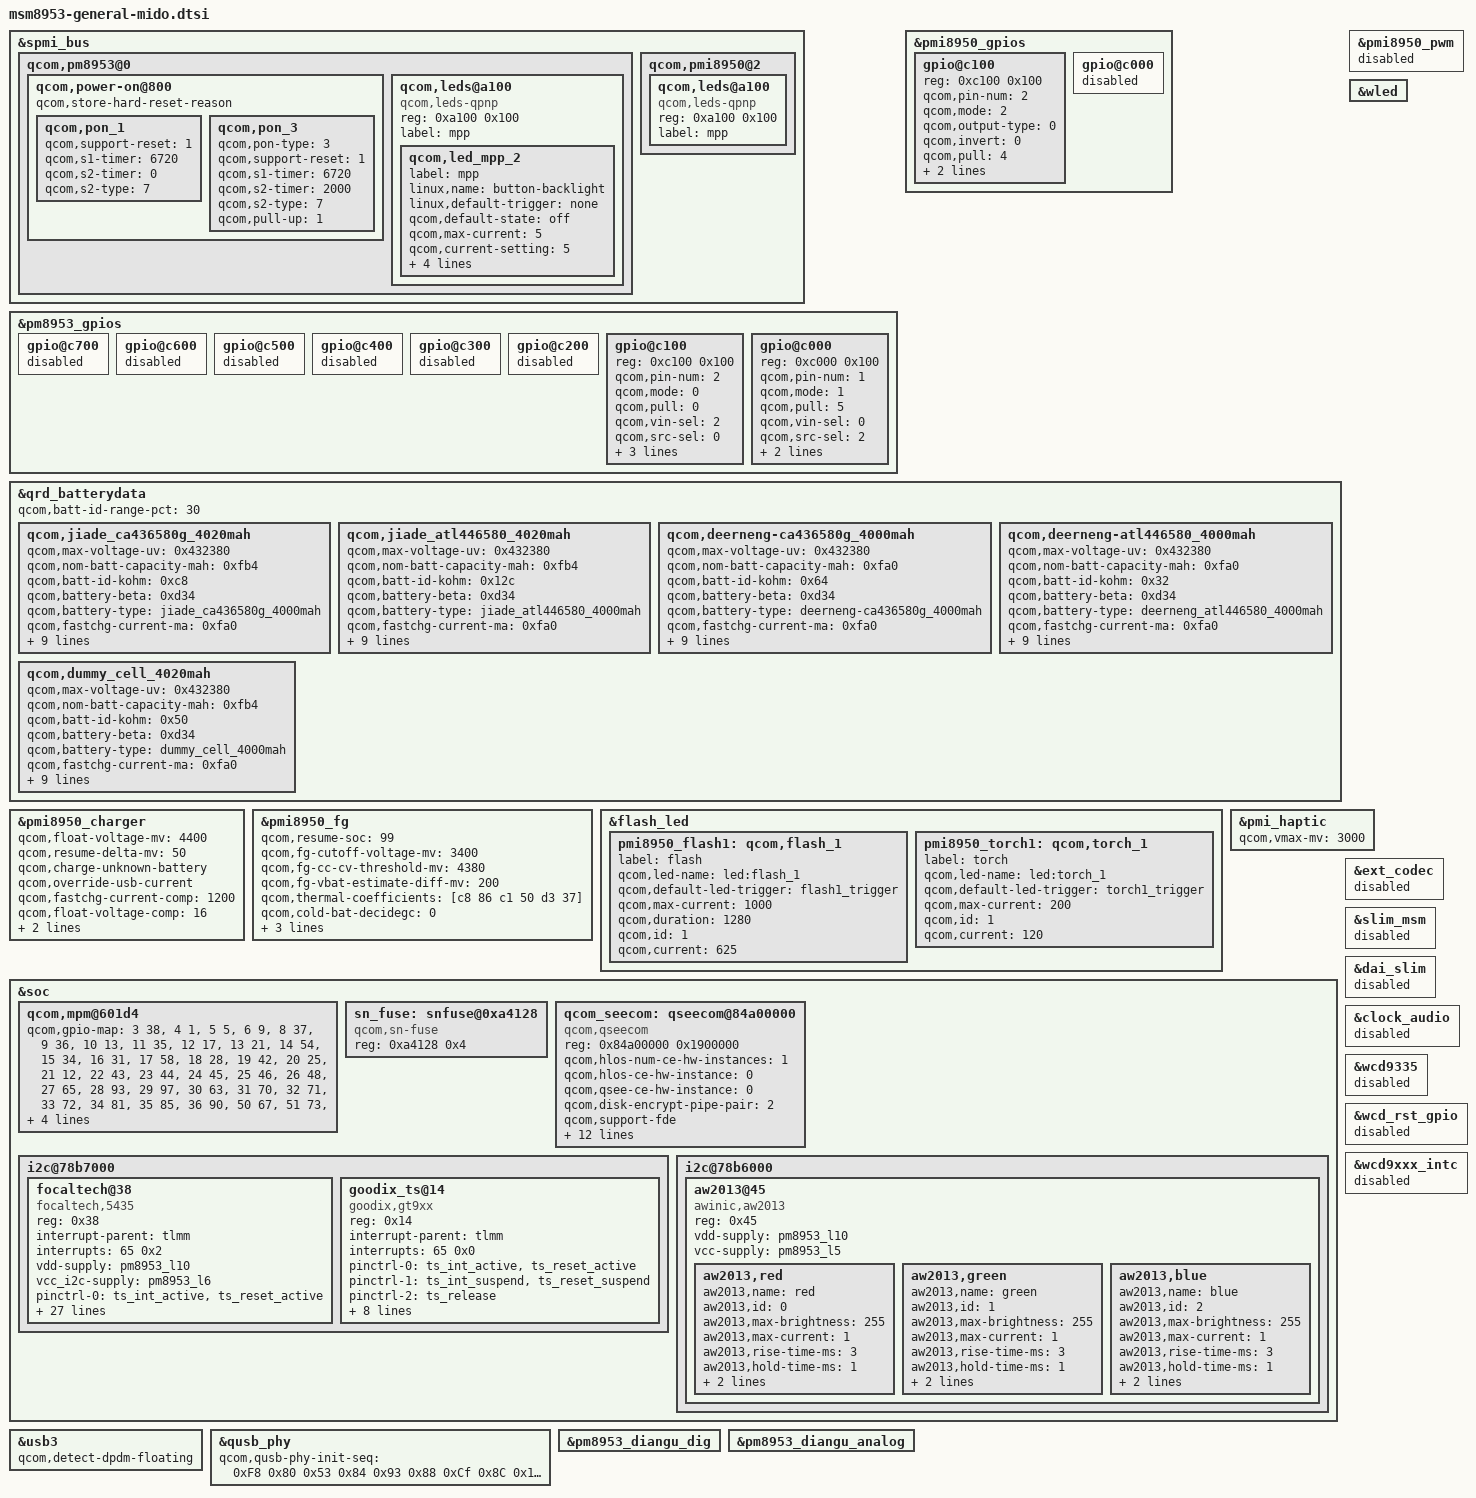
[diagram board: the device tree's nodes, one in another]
/* Copyright (c) 2017, The Linux Foundation. All rights reserved.
 *
 * This program is free software; you can redistribute it and/or modify
 * it under the terms of the GNU General Public License version 2 and
 * only version 2 as published by the Free Software Foundation.
 *
 * This program is distributed in the hope that it will be useful,
 * but WITHOUT ANY WARRANTY; without even the implied warranty of
 * MERCHANTABILITY or FITNESS FOR A PARTICULAR PURPOSE.  See the
 * GNU General Public License for more details.
 */

&spmi_bus {
	qcom,pm8953@0 {
		qcom,power-on@800 {
                       qcom,store-hard-reset-reason;
			qcom,pon_1 {
				qcom,support-reset = <1>;
				qcom,s1-timer = <6720>;
				qcom,s2-timer = <0>;
				qcom,s2-type = <7>;
			};
			qcom,pon_3 {
				qcom,pon-type = <3>;
				qcom,support-reset = <1>;
				qcom,s1-timer = <6720>;
				qcom,s2-timer = <2000>;
				qcom,s2-type = <7>;
				qcom,pull-up = <1>;
			};
		};
                qcom,leds@a100 {
                        status = "okay";
                        compatible = "qcom,leds-qpnp";
                        reg = <0xa100 0x100>;
                        label = "mpp";
                        qcom,led_mpp_2 {
                                label = "mpp";
                                linux,name = "button-backlight";
                                linux,default-trigger = "none";
                                qcom,default-state = "off";
                                qcom,max-current = <5>;
                                qcom,current-setting = <5>;
                                qcom,id = <6>;
                                qcom,mode = "manual";
                                qcom,source-sel = <1>;
                                qcom,mode-ctrl = <0x61>;
                        };
                };
		/delete-node/ qcom,pm8953_typec@bf00;
	};

	qcom,pmi8950@2 {
		qcom,leds@a100 {
			compatible = "qcom,leds-qpnp";
			reg = <0xa100 0x100>;
			label = "mpp";
			/delete-node/ qcom,led_mpp_2;
		};
	};
};

&pm8953_gpios {
	gpio@c700 {
		status = "disabled";
	};
    
    gpio@c600 {
		status = "disabled";
	};
    
    gpio@c500 {
		status = "disabled";
	};
    
    gpio@c400 {
		status = "disabled";
	};
    
    gpio@c300 {
		status = "disabled";
	};
    
    gpio@c200 {
		status = "disabled";
	};
    
    gpio@c100 {
        reg = <0xc100 0x100>;
        qcom,pin-num = <2>;
        qcom,mode = <0>;
        qcom,pull = <0>;
        qcom,vin-sel = <2>;
        qcom,src-sel = <0>;
        qcom,master-en = <1>;
        qcom,out-strength = <3>;
        qcom,output-type = <0>;
        status = "okay";
    };
    
    gpio@c000 {
        reg = <0xc000 0x100>;
        qcom,pin-num = <1>;
        qcom,mode = <1>;
        qcom,pull = <5>;
        qcom,vin-sel = <0>;
        qcom,src-sel = <2>;
        qcom,master-en = <1>;
        qcom,out-strength = <2>;
        status = "okay";
    };
};

&pmi8950_gpios {
    gpio@c100 {
        reg = <0xc100 0x100>;
        qcom,pin-num = <2>;
        qcom,mode = <2>;
        qcom,output-type = <0>;
        qcom,invert = <0>;
        qcom,pull = <4>;
        qcom,out-strength = <3>;
        qcom,master-en = <1>;
        status = "okay";
    };
    
	gpio@c000 {
		status = "disabled";
	};
};

&qrd_batterydata {
	qcom,batt-id-range-pct = <30>;
    
	qcom,jiade_ca436580g_4020mah {
        qcom,max-voltage-uv = <0x432380>;
        qcom,nom-batt-capacity-mah = <0xfb4>;
        qcom,batt-id-kohm = <0xc8>;
        qcom,battery-beta = <0xd34>;
        qcom,battery-type = "jiade_ca436580g_4000mah";
        qcom,fastchg-current-ma = <0xfa0>;
        qcom,fg-cc-cv-threshold-mv = <0x1126>;
        qcom,chg-rslow-comp-c1 = <0x3840d2>;
        qcom,chg-rslow-comp-c2 = <0x627b75>;
        qcom,chg-rs-to-rslow = <0xb9ddd>;
        qcom,chg-rslow-comp-thr = <0xb7>;
        qcom,checksum = <0x952e>;
        qcom,gui-version = "PMI8950GUI - 2.0.0.16";
        qcom,fg-profile-data = <0xf0836d7d 0x9881227c 0x5d83656c 0x4b839b8d 0xeb813a9a 0x85bc71c8 0x5b110188 0x977da281 0x217c5283 0xa969ae79 0xbe861f82 0x739abebd 0x2fcb5a0e 0xdc0f8359 0x1470eefc 0x47447b3f 0xeb400000 0x5466930 0xfe1a0000 0x0 0x0 0x2b6bd169 0x6a731291 0x93776c71 0x46765f71 0x5e75426b 0x96666a2 0x24da5b73 0x5da0710c 0x2800ff36 0xf0113003 0xc>;
    };

    qcom,jiade_atl446580_4020mah {
        qcom,max-voltage-uv = <0x432380>;
        qcom,nom-batt-capacity-mah = <0xfb4>;
        qcom,batt-id-kohm = <0x12c>;
        qcom,battery-beta = <0xd34>;
        qcom,battery-type = "jiade_atl446580_4000mah";
        qcom,fastchg-current-ma = <0xfa0>;
        qcom,fg-cc-cv-threshold-mv = <0x1126>;
        qcom,chg-rslow-comp-c1 = <0x2ddb09>;
        qcom,chg-rslow-comp-c2 = <0x3cda94>;
        qcom,chg-rs-to-rslow = <0xc8771>;
        qcom,chg-rslow-comp-thr = <0x9f>;
        qcom,checksum = <0xb43>;
        qcom,gui-version = "PMI8950GUI - 2.0.0.16";
        qcom,fg-profile-data = <0xec833f7d 0x7181f677 0x55839752 0x52804587 0x1682ab9a 0xf3bd44cb 0x5b0e0588 0xeb7dde81 0x557c4f83 0x42704270 0x55845082 0x9299d5bc 0xb0c95a0d 0xb50f5059 0x1470eefc 0x833f1d3e 0x7b400000 0x4345bc30 0x3f290000 0x0 0x0 0xec6aed69 0x8978f789 0x546f5463 0x6b610a80 0xf06cd25b 0xa17c2ea1 0x1a1162e3 0x5fa0710c 0x2800ff36 0xf0113003 0xc>;
    };

    qcom,deerneng-ca436580g_4000mah {
        qcom,max-voltage-uv = <0x432380>;
        qcom,nom-batt-capacity-mah = <0xfa0>;
        qcom,batt-id-kohm = <0x64>;
        qcom,battery-beta = <0xd34>;
        qcom,battery-type = "deerneng-ca436580g_4000mah";
        qcom,fastchg-current-ma = <0xfa0>;
        qcom,fg-cc-cv-threshold-mv = <0x1126>;
        qcom,chg-rslow-comp-c1 = <0x2eec11>;
        qcom,chg-rslow-comp-c2 = <0x4856fb>;
        qcom,chg-rs-to-rslow = <0xa7bf6>;
        qcom,chg-rslow-comp-thr = <0xac>;
        qcom,checksum = <0xc816>;
        qcom,gui-version = "PMI8950GUI - 2.0.0.16";
        qcom,fg-profile-data = <0xf183767d 0x8d81017c 0x5b831667 0xe582728d 0xa82fa99 0x8bbcabc8 0x5a0f0288 0xbd7dbe81 0x317c4f83 0xd6bff72 0x3852782 0x3e9a7dbd 0xbeca5a0e 0xcd0fbb58 0x1470eefc 0x4545e937 0x363b0000 0x5345392a 0xdd370000 0x0 0x0 0x5c6a7769 0x9c631d80 0xc4675a60 0xcf629e79 0xcc640359 0x7c7e7a91 0x1d0161f7 0x5da0710c 0x2800ff36 0xf0113003 0xc>;
    };

    qcom,deerneng-atl446580_4000mah {
        qcom,max-voltage-uv = <0x432380>;
        qcom,nom-batt-capacity-mah = <0xfa0>;
        qcom,batt-id-kohm = <0x32>;
        qcom,battery-beta = <0xd34>;
        qcom,battery-type = "deerneng_atl446580_4000mah";
        qcom,fastchg-current-ma = <0xfa0>;
        qcom,fg-cc-cv-threshold-mv = <0x1126>;
        qcom,chg-rslow-comp-c1 = <0x30d3ae>;
        qcom,chg-rslow-comp-c2 = <0x43103e>;
        qcom,chg-rs-to-rslow = <0xca280>;
        qcom,chg-rslow-comp-thr = <0xa2>;
        qcom,checksum = <0x8aaf>;
        qcom,gui-version = "PMI8950GUI - 2.0.0.16";
        qcom,fg-profile-data = <0xdf83c87c 0x19815577 0x6183ba6f 0x36895c94 0x3282b299 0xb3bc3ec9 0x550ffa83 0x497d5b81 0xa4775f83 0xab5deb83 0xc28f4982 0x89a75bd 0xaeca520d 0xb60f6859 0x1470eefc 0x6e3e0c45 0xe6410000 0x5a461c30 0x1e2a0000 0x0 0x0 0x6f6bfb69 0x9971a98b 0xfb75d06b 0x216d1579 0x2a6f2d68 0x583504a8 0x214163ff 0x64a0710c 0x2800ff36 0xf0113003 0xc>;
    };

    qcom,dummy_cell_4020mah {
        qcom,max-voltage-uv = <0x432380>;
        qcom,nom-batt-capacity-mah = <0xfb4>;
        qcom,batt-id-kohm = <0x50>;
        qcom,battery-beta = <0xd34>;
        qcom,battery-type = "dummy_cell_4000mah";
        qcom,fastchg-current-ma = <0xfa0>;
        qcom,fg-cc-cv-threshold-mv = <0x1126>;
        qcom,chg-rslow-comp-c1 = <0x3840d2>;
        qcom,chg-rslow-comp-c2 = <0x627b75>;
        qcom,chg-rs-to-rslow = <0xb9ddd>;
        qcom,chg-rslow-comp-thr = <0xb7>;
        qcom,checksum = <0x952e>;
        qcom,gui-version = "PMI8950GUI - 2.0.0.16";
        qcom,fg-profile-data = <0xf0836d7d 0x9881227c 0x5d83656c 0x4b839b8d 0xeb813a9a 0x85bc71c8 0x5b110188 0x977da281 0x217c5283 0xa969ae79 0xbe861f82 0x739abebd 0x2fcb5a0e 0xdc0f8359 0x1470eefc 0x47447b3f 0xeb400000 0x5466930 0xfe1a0000 0x0 0x0 0x2b6bd169 0x6a731291 0x93776c71 0x46765f71 0x5e75426b 0x96666a2 0x24da5b73 0x5da0710c 0x2800ff36 0xf0113003 0xc>;
    };
	/delete-node/ qcom,qrd_msm8937_sku1_2920mah;

};


&pmi8950_charger {
	qcom,float-voltage-mv = <4400>;
	qcom,resume-delta-mv = <50>;
	qcom,charge-unknown-battery;
	qcom,override-usb-current;
	qcom,fastchg-current-comp = <1200>;
	qcom,float-voltage-comp = <16>;
	qcom,thermal-mitigation = <3000 2500 2000 2000 1000 500 0>;
	/delete-property/ qcom,parallel-usb-min-current-ma;
	/delete-property/ qcom,parallel-usb-9v-min-current-ma;
	/delete-property/ qcom,parallel-allowed-lowering-ma;
	/delete-property/ qcom,chg-led-sw-controls;
	/delete-property/ qcom,chg-led-support;
	/delete-property/ qcom,external-typec;
	/delete-property/ qcom,typec-psy-name;
	/delete-property/ qcom,autoadjust-vfloat;
};

&pmi8950_fg {
	qcom,resume-soc = <99>;
	qcom,fg-cutoff-voltage-mv = <3400>;
	qcom,fg-cc-cv-threshold-mv = <4380>;
	qcom,fg-vbat-estimate-diff-mv = <200>;
	qcom,thermal-coefficients = [c8 86 c1 50 d3 37];
	qcom,cold-bat-decidegc = <0>;
	qcom,cool-bat-decidegc = <150>;
	qcom,warm-bat-decidegc = <450>;
	qcom,fg-restore-batt-info;

};

&pmi8950_pwm {
	status = "disabled";
};

&wled {
	/delete-property/ qcom,en-ext-pfet-sc-pro;
};

&flash_led {
	pmi8950_flash1: qcom,flash_1 {
		label = "flash";
		qcom,led-name = "led:flash_1";
		qcom,default-led-trigger = "flash1_trigger";
		qcom,max-current = <1000>;
		qcom,duration = <1280>;
		qcom,id = <1>;
		qcom,current = <625>;
	};
	
	pmi8950_torch1: qcom,torch_1 {
		label = "torch";
		qcom,led-name = "led:torch_1";
		qcom,default-led-trigger = "torch1_trigger";
		qcom,max-current = <200>;
		qcom,id = <1>;
		qcom,current = <120>;
	};
};

&pmi_haptic {
	qcom,vmax-mv = <3000>;
};

&soc {
	qcom,mpm@601d4 {
		qcom,gpio-map = <3  38 >,
                        <4  1 >,
                        <5  5 >,
                        <6  9 >,
                        <8  37>,
                        <9  36>,
                        <10  13>,
                        <11  35>,
                        <12  17>,
                        <13  21>,
                        <14  54>,
                        <15  34>,
                        <16  31>,
                        <17  58>,
                        <18  28>,
                        <19  42>,
                        <20  25>,
                        <21  12>,
                        <22  43>,
                        <23  44>,
                        <24  45>,
                        <25  46>,
                        <26  48>,
                        <27  65>,
                        <28  93>,
                        <29  97>,
                        <30  63>,
                        <31  70>,
                        <32  71>,
                        <33  72>,
                        <34  81>,
                        <35  85>,
                        <36  90>,
                        <50  67>,
                        <51  73>,
                        <52  74>,
                        <53  62>,
                        <59  59>,
                        <60  60>,
                        <61  61>,
                        <62  86>,
                        <63  87>,
                        <64  91>,
                        <65  129>,
                        <66  130>,
                        <67  131>,
                        <68  132>,
                        <69  133>,
                        <70  137>,
                        <71  138>,
                        <72  139>,
                        <73  140>,
                        <74  141>,
                        <0xff 24>, /* added by xiaomi */
                        <0xff 88>;
		};
	sn_fuse: snfuse@0xa4128 {
		compatible = "qcom,sn-fuse";
		reg = <0xa4128 0x4>;
		reg-names = "sn-base";
	};

	qcom_seecom: qseecom@84a00000 { /* renamed from caf qseecom@85b00000 */
                compatible = "qcom,qseecom";
                reg = <0x84a00000 0x1900000>; /* changed by xiaomi */
                reg-names = "secapp-region";
                qcom,hlos-num-ce-hw-instances = <1>;
                qcom,hlos-ce-hw-instance = <0>;
                qcom,qsee-ce-hw-instance = <0>;
                qcom,disk-encrypt-pipe-pair = <2>;
                qcom,support-fde;
                qcom,msm-bus,name = "qseecom-noc";
                qcom,msm-bus,num-cases = <4>;
                qcom,msm-bus,num-paths = <1>;
                qcom,support-bus-scaling;
                qcom,msm-bus,vectors-KBps =
                        <55 512 0 0>,
                        <55 512 0 0>,
                        <55 512 120000 1200000>,
                        <55 512 393600 3936000>;
                clocks = <&clock_gcc clk_crypto_clk_src>,
                         <&clock_gcc clk_gcc_crypto_clk>,
                         <&clock_gcc clk_gcc_crypto_ahb_clk>,
                         <&clock_gcc clk_gcc_crypto_axi_clk>;
                clock-names = "core_clk_src", "core_clk",
                                "iface_clk", "bus_clk";
                qcom,ce-opp-freq = <100000000>;
        };

        /delete-node/ qseecom@85b00000;

	i2c@78b7000 {
                focaltech@38 {
                        compatible = "focaltech,5435";
                        reg = <0x38>;
                        interrupt-parent = <&tlmm>;
                        interrupts = <65 0x2>;
                        vdd-supply = <&pm8953_l10>;
                        vcc_i2c-supply = <&pm8953_l6>;
                        /* pins used by touchscreen */
                        pinctrl-names = "pmx_ts_active","pmx_ts_suspend",
                                                        "pmx_ts_release";
                        pinctrl-0 = <&ts_int_active &ts_reset_active>;
                        pinctrl-1 = <&ts_int_suspend &ts_reset_suspend>;
                        pinctrl-2 = <&ts_release>;
                        focaltech,name = "ft5435";
                        focaltech,family-id = <0x54>;
                        focaltech,reset-gpio = <&tlmm 64 0x0>;
                        focaltech,irq-gpio = <&tlmm 65 0x2008>;
                        focaltech,display-coords = <0 0 1080 1920>;
                        focaltech,panel-coords = <0 0 1080 1920>;
                        focaltech,no-force-update;
                        focaltech,i2c-pull-up;
                        focaltech,group-id = <1>;
                        focaltech,hard-reset-delay-ms = <200>;
                        focaltech,soft-reset-delay-ms = <200>;
                        focaltech,num-max-touches = <10>;
                        focaltech,fw-delay-aa-ms = <2>;
                        focaltech,fw-delay-55-ms = <2>;
                        focaltech,fw-upgrade-id1 = <0x54>;
                        focaltech,fw-upgrade-id2 = <0x2c>;
                        focaltech,fw-delay-readid-ms = <10>;
                        focaltech,fw-delay-era-flsh-ms = <2000>;
                        focaltech,fw-auto-cal;
                        focaltech,fw-vkey-support;
                        focaltech,resume-in-workqueue;
                        focaltech,num-virtual-key = <3>;
                        focal,virtual_key_1 = <172 500 2040>;/*home*/
                        focal,virtual_key_2 = <139 200 2040>;/*menu*/
                        focal,virtual_key_3 = <158 800 2040>;/*back*/
                };

		goodix_ts@14 {
			compatible = "goodix,gt9xx";
			reg = <0x14>;
			interrupt-parent = <&tlmm>;
			interrupts = <65 0x0>;
			pinctrl-names = "pmx_ts_active","pmx_ts_suspend",
			"pmx_ts_release";
			pinctrl-0 = <&ts_int_active &ts_reset_active>;
			pinctrl-1 = <&ts_int_suspend &ts_reset_suspend>;
			pinctrl-2 = <&ts_release>;
			vdd_ana-supply = <&pm8953_l10>;
			vcc_i2c-supply = <&pm8953_l6>;
			goodix,rst-gpio = <&tlmm 64 0x0>;
			goodix,irq-gpio = <&tlmm 65 0x2008>;
			goodix,cfg-group0 = [45 38 04 80 07 0A 35 41 01 0A
					26 0B 5A 32 05 05 00 00 00 00
					00 00 05 14 14 26 14 8C 2E 0E
					4A 4C F4 0A F4 0A 00 BA 33 11
					00 00 00 00 00 05 03 28 78 96
					3A 1E 5A 8F 90 03 00 00 00 04
					CE 21 00 B0 29 28 98 34 00 87
					41 60 7B 51 00 7B 18 38 60 00
					F0 55 40 AA A0 27 00 04 53 00
					00 00 00 00 00 02 00 00 00 00
					00 00 00 00 00 00 3C 00 00 00
					00 28 02 04 06 08 0A 0C 0E 10
					12 14 16 18 1A 1C 00 00 00 00
					00 00 00 00 00 00 00 00 00 00
					00 00 00 02 04 06 08 0A 0C 0F
					10 12 13 14 16 18 1C 1D 1E 1F
					20 21 22 24 26 28 29 2A 00 00
					00 00 00 00 00 00 00 00 00 00
					00 00 00 00 23 01];
			goodix,cfg-group1 = [49 38 04 80 07 0A 3D 49 01 48
					50 0F 50 41 03 65 00 00 00 00
					00 00 0F 16 1A 23 14 87 27 DD
					50 52 E7 07 E7 07 00 42 33 91
					0A 00 00 00 00 83 C4 14 14 C8
					02 3C 64 8F D0 03 05 1E 00 04
					93 3F 00 8A 46 00 82 4D 00 7C
					55 00 76 5F 00 76 18 38 60 00
					F7 55 40 99 99 17 00 00 D1 00
					00 00 00 00 00 02 00 00 05 28
					00 00 00 00 00 28 64 00 00 00
					00 50 0C 0B 0A 09 08 07 06 05
					04 03 02 01 00 0D 0E 0F 10 11
					12 13 14 15 16 17 18 19 1A FF
					FF FF 29 28 24 22 20 1F 1E 0A
					08 06 05 04 02 00 FF FF FF 00
					00 00 00 00 00 00 00 00 28 32
					3C 10 23 28 0F 00 00 00 00 00
					00 00 0F 4B 00 00 00 00 00 00
					1E 50 00 00 00 05 00 00 00 00
					01 14 78 1A 19 3C 28 00 00 00
					00 00 00 00 00 00 00 00 00 00
					00 00 00 00 00 00 83 01];
		};

        };

	i2c@78b6000 { /* BLSP1 QUP3 */
                aw2013@45 {
                        compatible = "awinic,aw2013";
                        reg = <0x45>;
                        vdd-supply = <&pm8953_l10>;
                        vcc-supply = <&pm8953_l5>;

                        aw2013,red {
                                aw2013,name = "red";
                                aw2013,id = <0>;
                                aw2013,max-brightness = <255>;
                                aw2013,max-current = <1>;
                                aw2013,rise-time-ms = <3>;
                                aw2013,hold-time-ms = <1>;
                                aw2013,fall-time-ms = <3>;
                                aw2013,off-time-ms = <3>;
                        };

                        aw2013,green {
                                aw2013,name = "green";
                                aw2013,id = <1>;
                                aw2013,max-brightness = <255>;
                                aw2013,max-current = <1>;
                                aw2013,rise-time-ms = <3>;
                                aw2013,hold-time-ms = <1>;
                                aw2013,fall-time-ms = <3>;
                                aw2013,off-time-ms = <3>;
                        };

                        aw2013,blue {
                                aw2013,name = "blue";
                                aw2013,id = <2>;
                                aw2013,max-brightness = <255>;
                                aw2013,max-current = <1>;
                                aw2013,rise-time-ms = <3>;
                                aw2013,hold-time-ms = <1>;
                                aw2013,fall-time-ms = <3>;
                                aw2013,off-time-ms = <3>;
                        };
                };
        };
};

&usb3 {
	qcom,detect-dpdm-floating;
};

&qusb_phy {
	qcom,qusb-phy-init-seq = <0xF8 0x80
					0x53 0x84 /* changed by xiaomi */
					0x93 0x88 /* changed by xiaomi */
					0xCf 0x8C /* changed by xiaomi */
					0x14 0x9C
					0x30 0x08
					0x79 0x0C
					0x21 0x10
					0x00 0x90
					0x9F 0x1C
					0x00 0x18>;
};


&pm8953_diangu_dig {
	status = "ok";
};

&pm8953_diangu_analog {
	status = "ok";
};

&ext_codec {
	status = "disabled";
};

&slim_msm {
	status = "disabled";
};

&dai_slim {
	status = "disabled";
};

&clock_audio {
	status = "disabled";
};

&wcd9335 {
	status = "disabled";
};

&wcd_rst_gpio {
	status = "disabled";
};

&wcd9xxx_intc {
	status = "disabled";
};
